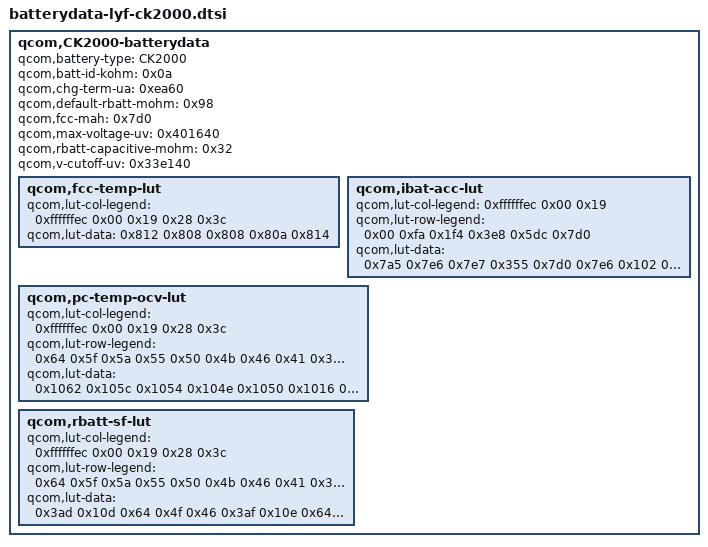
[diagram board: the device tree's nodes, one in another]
qcom,CK2000-batterydata {
			qcom,battery-type = "CK2000";
			qcom,batt-id-kohm = <0x0a>;
			qcom,chg-term-ua = <0xea60>;
			qcom,default-rbatt-mohm = <0x98>;
			qcom,fcc-mah = <0x7d0>;
			qcom,max-voltage-uv = <0x401640>;
			qcom,rbatt-capacitive-mohm = <0x32>;
			qcom,v-cutoff-uv = <0x33e140>;

			qcom,fcc-temp-lut {
				qcom,lut-col-legend = <0xffffffec 0x00 0x19 0x28 0x3c>;
				qcom,lut-data = <0x812 0x808 0x808 0x80a 0x814>;
			};

			qcom,ibat-acc-lut {
				qcom,lut-col-legend = <0xffffffec 0x00 0x19>;
				qcom,lut-row-legend = <0x00 0xfa 0x1f4 0x3e8 0x5dc 0x7d0>;
				qcom,lut-data = <0x7a5 0x7e6 0x7e7 0x355 0x7d0 0x7e6 0x102 0x76e 0x7d6 0x22 0x5b4 0x7bc 0x09 0x369 0x766 0x0b 0x1bc 0x681>;
			};

			qcom,pc-temp-ocv-lut {
				qcom,lut-col-legend = <0xffffffec 0x00 0x19 0x28 0x3c>;
				qcom,lut-row-legend = <0x64 0x5f 0x5a 0x55 0x50 0x4b 0x46 0x41 0x3c 0x37 0x32 0x2d 0x28 0x23 0x1e 0x19 0x14 0x10 0x0d 0x0b 0x0a 0x09 0x08 0x07 0x06 0x05 0x04 0x03 0x02 0x01 0x00>;
				qcom,lut-data = <0x1062 0x105c 0x1054 0x104e 0x1050 0x1016 0x1017 0x1013 0x1010 0x1014 0xfee 0xff2 0xfee 0xfe6 0xfe6 0xf98 0xfa4 0xfb1 0xfb4 0xfbc 0xf5c 0xf72 0xf86 0xf8e 0xf96 0xf40 0xf58 0xf71 0xf72 0xf73 0xf27 0xf3d 0xf54 0xf54 0xf54 0xf0b 0xf1f 0xf36 0xf38 0xf38 0xef0 0xf04 0xf14 0xf19 0xf1a 0xeda 0xeee 0xef4 0xef5 0xef8 0xeca 0xeda 0xedf 0xede 0xede 0xebc 0xeca 0xed0 0xed0 0xecf 0xeae 0xebe 0xec5 0xec5 0xec4 0xea0 0xeb4 0xebe 0xebc 0xeba 0xe91 0xea9 0xeb7 0xeb2 0xeab 0xe7e 0xe9d 0xeab 0xea4 0xe96 0xe65 0xe92 0xe9a 0xe91 0xe84 0xe4a 0xe88 0xe85 0xe7c 0xe70 0xe30 0xe7e 0xe70 0xe68 0xe5b 0xe15 0xe76 0xe6a 0xe62 0xe56 0xe03 0xe72 0xe68 0xe60 0xe56 0xdee 0xe6c 0xe68 0xe60 0xe54 0xdd1 0xe64 0xe66 0xe5e 0xe52 0xdac 0xe58 0xe62 0xe5a 0xe4e 0xd77 0xe44 0xe58 0xe50 0xe40 0xd34 0xe28 0xe3a 0xe30 0xe1e 0xcf4 0xe00 0xe0c 0xe00 0xdee 0xcbc 0xdc8 0xdce 0xdc3 0xdb0 0xc60 0xd78 0xd7c 0xd71 0xd5c 0xc1a 0xcf5 0xcfe 0xcf2 0xce0 0xbb8 0xbb8 0xbb8 0xbb8 0xbb8>;
			};

			qcom,rbatt-sf-lut {
				qcom,lut-col-legend = <0xffffffec 0x00 0x19 0x28 0x3c>;
				qcom,lut-row-legend = <0x64 0x5f 0x5a 0x55 0x50 0x4b 0x46 0x41 0x3c 0x37 0x32 0x2d 0x28 0x23 0x1e 0x19 0x14 0x10 0x0d 0x0b 0x0a 0x09 0x08 0x07 0x06 0x05 0x04 0x03 0x02 0x01>;
				qcom,lut-data = <0x3ad 0x10d 0x64 0x4f 0x46 0x3af 0x10e 0x64 0x4f 0x46 0x3d4 0x11c 0x6b 0x51 0x47 0x3b9 0x118 0x6b 0x54 0x48 0x3b1 0x116 0x6f 0x56 0x4a 0x3c6 0x117 0x78 0x59 0x4c 0x3d7 0x114 0x7d 0x5e 0x4f 0x3df 0x110 0x81 0x64 0x52 0x3f1 0x10e 0x76 0x64 0x54 0x403 0x10d 0x66 0x56 0x4c 0x41d 0x10c 0x63 0x4f 0x47 0x443 0x10b 0x64 0x50 0x48 0x475 0x10c 0x64 0x53 0x4a 0x4bc 0x10e 0x67 0x54 0x4d 0x517 0x110 0x69 0x54 0x4a 0x57d 0x117 0x6a 0x51 0x47 0x5e4 0x127 0x6b 0x52 0x48 0x634 0x138 0x6b 0x53 0x49 0x5ab 0x135 0x63 0x50 0x47 0x5a6 0x12d 0x63 0x4f 0x47 0x5fc 0x131 0x64 0x51 0x48 0x69a 0x138 0x68 0x53 0x4a 0x7af 0x13e 0x6c 0x56 0x4c 0xa35 0x144 0x72 0x58 0x4d 0x13f3 0x14a 0x73 0x57 0x4b 0x27e5 0x153 0x6e 0x54 0x4a 0x4fca 0x165 0x6f 0x56 0x4b 0x9f95 0x187 0x76 0x5a 0x50 0x13f29 0x1eb 0x85 0x64 0x5d 0x27e53 0x3d7 0x10a 0xc8 0x97>;
			};
		};
